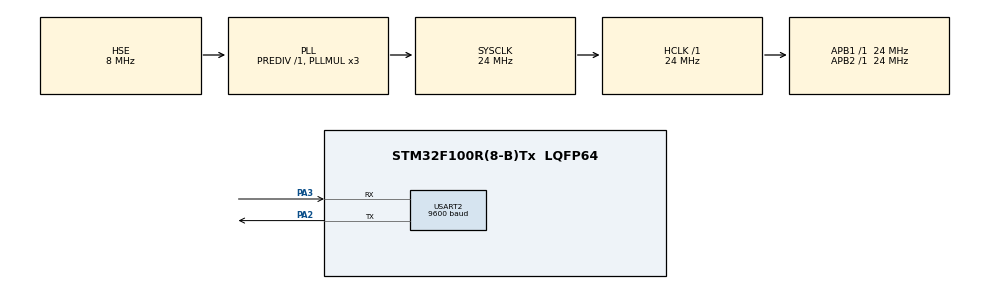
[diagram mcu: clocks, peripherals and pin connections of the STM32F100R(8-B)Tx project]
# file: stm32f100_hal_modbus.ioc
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Mcu.Family=STM32F1
Mcu.Name=STM32F100R(8-B)Tx
Mcu.Package=LQFP64
NVIC.PriorityGroup=NVIC_PRIORITYGROUP_4
NVIC.TIM6_DAC_IRQn=true\:0\:0\:false\:false\:true\:true\:true
PA13.Mode=Serial_Wire
PA13.Signal=SYS_JTMS-SWDIO
PA14.Mode=Serial_Wire
PA14.Signal=SYS_JTCK-SWCLK
PA2.Mode=Asynchronous
PA2.Signal=USART2_TX
PA3.Mode=Asynchronous
PA3.Signal=USART2_RX
PC14-OSC32_IN.Mode=LSE-External-Oscillator
PC14-OSC32_IN.Signal=RCC_OSC32_IN
PC15-OSC32_OUT.Mode=LSE-External-Oscillator
PC15-OSC32_OUT.Signal=RCC_OSC32_OUT
PD0-OSC_IN.Mode=HSE-External-Oscillator
PD0-OSC_IN.Signal=RCC_OSC_IN
PD1-OSC_OUT.Mode=HSE-External-Oscillator
PD1-OSC_OUT.Signal=RCC_OSC_OUT
ProjectManager.HeapSize=0x200
ProjectManager.StackSize=0x400
ProjectManager.TargetToolchain=STM32CubeIDE
RCC.AHBFreq_Value=24000000
RCC.APB1Freq_Value=24000000
RCC.APB1TimFreq_Value=24000000
RCC.APB2Freq_Value=24000000
RCC.APB2TimFreq_Value=24000000
RCC.HCLKFreq_Value=24000000
RCC.PLLMUL=RCC_PLL_MUL3
RCC.PLLSource=RCC_PLLSOURCE_HSE
RCC.SYSCLKFreq_VALUE=24000000
RCC.SYSCLKSource=RCC_SYSCLKSOURCE_PLLCLK
TIM6.Period=49
TIM6.Prescaler=23
USART2.BaudRate=9600
USART2.VirtualMode=VM_ASYNC
VP_TIM6_VS_ClockSourceINT.Mode=Enable_Timer
board=custom

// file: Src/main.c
/* USER CODE BEGIN Header */
/**
  ******************************************************************************
  * @file           : main.c
  * @brief          : Main program body
  ******************************************************************************
  * @attention
  *
  * <h2><center>&copy; Copyright (c) 2019 STMicroelectronics.
  * All rights reserved.</center></h2>
  *
  * This software component is licensed by ST under BSD 3-Clause license,
  * the "License"; You may not use this file except in compliance with the
  * License. You may obtain a copy of the License at:
  *                        opensource.org/licenses/BSD-3-Clause
  *
  ******************************************************************************
  */
/* USER CODE END Header */

#include "main.h"

/* USER CODE BEGIN Includes */
#include "mb.h"
#include "mbport.h"

/* USER CODE END Includes */

/* USER CODE BEGIN PD */

#define REG_INPUT_START 1000
#define REG_INPUT_NREGS 4

#define REG_HOLDING_START 1000
#define REG_HOLDING_NREGS 4

/* USER CODE END PD */

TIM_HandleTypeDef htim6;

UART_HandleTypeDef huart2;

/* USER CODE BEGIN PV */

static USHORT   usRegInputStart = REG_INPUT_START;
static USHORT   usRegInputBuf[REG_INPUT_NREGS];

static USHORT   usRegHoldingStart = REG_HOLDING_START;
static USHORT   usRegHoldingBuf[REG_HOLDING_NREGS];

/* USER CODE END PV */

void SystemClock_Config(void);
static void MX_GPIO_Init(void);
static void MX_TIM6_Init(void);
static void MX_USART2_UART_Init(void);

/* USER CODE BEGIN 0 */

eMBErrorCode
eMBRegInputCB( UCHAR * pucRegBuffer, USHORT usAddress, USHORT usNRegs )
{
    eMBErrorCode    eStatus = MB_ENOERR;
    int             iRegIndex;

    if( ( usAddress >= REG_INPUT_START )
        && ( usAddress + usNRegs <= REG_INPUT_START + REG_INPUT_NREGS ) )
    {
        iRegIndex = ( int )( usAddress - usRegInputStart );
        while( usNRegs > 0 )
        {
            *pucRegBuffer++ =
                ( unsigned char )( usRegInputBuf[iRegIndex] >> 8 );
            *pucRegBuffer++ =
                ( unsigned char )( usRegInputBuf[iRegIndex] & 0xFF );
            iRegIndex++;
            usNRegs--;
        }
    }
    else
    {
        eStatus = MB_ENOREG;
    }

    return eStatus;
}

eMBErrorCode
eMBRegHoldingCB( UCHAR * pucRegBuffer, USHORT usAddress, USHORT usNRegs, eMBRegisterMode eMode )
{
    eMBErrorCode    eStatus = MB_ENOERR;
    int             iRegIndex;

    if( ( usAddress >= REG_HOLDING_START ) &&
        ( usAddress + usNRegs <= REG_HOLDING_START + REG_HOLDING_NREGS ) )
    {
        iRegIndex = ( int )( usAddress - usRegHoldingStart );
        switch ( eMode )
        {
            /* Pass current register values to the protocol stack. */
        case MB_REG_READ:
            while( usNRegs > 0 )
            {
                *pucRegBuffer++ = ( UCHAR ) ( usRegHoldingBuf[iRegIndex] >> 8 );
                *pucRegBuffer++ = ( UCHAR ) ( usRegHoldingBuf[iRegIndex] & 0xFF );
                iRegIndex++;
                usNRegs--;
            }
            break;

            /* Update current register values with new values from the
             * protocol stack. */
        case MB_REG_WRITE:
            while( usNRegs > 0 )
            {
                usRegHoldingBuf[iRegIndex] = *pucRegBuffer++ << 8;
                usRegHoldingBuf[iRegIndex] |= *pucRegBuffer++;
                iRegIndex++;
                usNRegs--;
            }
        }
    }
    else
    {
        eStatus = MB_ENOREG;
    }
    return eStatus;
}

eMBErrorCode
eMBRegCoilsCB( UCHAR * pucRegBuffer, USHORT usAddress, USHORT usNCoils,
               eMBRegisterMode eMode )
{
    return MB_ENOREG;
}

eMBErrorCode
eMBRegDiscreteCB( UCHAR * pucRegBuffer, USHORT usAddress, USHORT usNDiscrete )
{
    return MB_ENOREG;
}

static uint32_t lock_nesting_count = 0;
void __critical_enter(void)
{
    __disable_irq();
    ++lock_nesting_count;
}
void __critical_exit(void)
{
    /* Unlock interrupts only when we are exiting the outermost nested call. */
    --lock_nesting_count;
    if (lock_nesting_count == 0) {
        __enable_irq();
    }
}

/* USER CODE END 0 */

int main(void)
{

  /* MCU Configuration--------------------------------------------------------*/

  /* Reset of all peripherals, Initializes the Flash interface and the Systick. */
  HAL_Init();

  /* Configure the system clock */
  SystemClock_Config();

  /* Initialize all configured peripherals */
  MX_GPIO_Init();
  MX_TIM6_Init();
  MX_USART2_UART_Init();
  /* USER CODE BEGIN 2 */

  	  eMBErrorCode    eStatus;
      eStatus = eMBInit( MB_RTU, 0x0A, 1, 9600, MB_PAR_NONE );

      /* Enable the Modbus Protocol Stack. */
      eStatus = eMBEnable(  );

  /* USER CODE END 2 */

  /* Infinite loop */
  while (1)
  {

    /* USER CODE BEGIN 3 */
	  ( void )eMBPoll(  );

	 /* Here we simply count the number of poll cycles. */
	    usRegInputBuf[1]++;
  }
  /* USER CODE END 3 */
}

void SystemClock_Config(void)
{
  RCC_OscInitTypeDef RCC_OscInitStruct = {0};
  RCC_ClkInitTypeDef RCC_ClkInitStruct = {0};

  /** Initializes the CPU, AHB and APB busses clocks
  */
  RCC_OscInitStruct.OscillatorType = RCC_OSCILLATORTYPE_HSE;
  RCC_OscInitStruct.HSEState = RCC_HSE_ON;
  RCC_OscInitStruct.HSEPredivValue = RCC_HSE_PREDIV_DIV1;
  RCC_OscInitStruct.PLL.PLLState = RCC_PLL_ON;
  RCC_OscInitStruct.PLL.PLLSource = RCC_PLLSOURCE_HSE;
  RCC_OscInitStruct.PLL.PLLMUL = RCC_PLL_MUL3;
  if (HAL_RCC_OscConfig(&RCC_OscInitStruct) != HAL_OK)
  {
    Error_Handler();
  }
  /** Initializes the CPU, AHB and APB busses clocks
  */
  RCC_ClkInitStruct.ClockType = RCC_CLOCKTYPE_HCLK|RCC_CLOCKTYPE_SYSCLK
                              |RCC_CLOCKTYPE_PCLK1|RCC_CLOCKTYPE_PCLK2;
  RCC_ClkInitStruct.SYSCLKSource = RCC_SYSCLKSOURCE_PLLCLK;
  RCC_ClkInitStruct.AHBCLKDivider = RCC_SYSCLK_DIV1;
  RCC_ClkInitStruct.APB1CLKDivider = RCC_HCLK_DIV1;
  RCC_ClkInitStruct.APB2CLKDivider = RCC_HCLK_DIV1;

  if (HAL_RCC_ClockConfig(&RCC_ClkInitStruct, FLASH_LATENCY_0) != HAL_OK)
  {
    Error_Handler();
  }
}

static void MX_TIM6_Init(void)
{

  TIM_MasterConfigTypeDef sMasterConfig = {0};

  htim6.Instance = TIM6;
  htim6.Init.Prescaler = 23;
  htim6.Init.CounterMode = TIM_COUNTERMODE_UP;
  htim6.Init.Period = 49;
  htim6.Init.AutoReloadPreload = TIM_AUTORELOAD_PRELOAD_DISABLE;
  if (HAL_TIM_Base_Init(&htim6) != HAL_OK)
  {
    Error_Handler();
  }
  sMasterConfig.MasterOutputTrigger = TIM_TRGO_RESET;
  sMasterConfig.MasterSlaveMode = TIM_MASTERSLAVEMODE_DISABLE;
  if (HAL_TIMEx_MasterConfigSynchronization(&htim6, &sMasterConfig) != HAL_OK)
  {
    Error_Handler();
  }

}

static void MX_USART2_UART_Init(void)
{

  huart2.Instance = USART2;
  huart2.Init.BaudRate = 9600;
  huart2.Init.WordLength = UART_WORDLENGTH_8B;
  huart2.Init.StopBits = UART_STOPBITS_1;
  huart2.Init.Parity = UART_PARITY_NONE;
  huart2.Init.Mode = UART_MODE_TX_RX;
  huart2.Init.HwFlowCtl = UART_HWCONTROL_NONE;
  huart2.Init.OverSampling = UART_OVERSAMPLING_16;
  if (HAL_UART_Init(&huart2) != HAL_OK)
  {
    Error_Handler();
  }

}

static void MX_GPIO_Init(void)
{

  /* GPIO Ports Clock Enable */
  __HAL_RCC_GPIOC_CLK_ENABLE();
  __HAL_RCC_GPIOD_CLK_ENABLE();
  __HAL_RCC_GPIOA_CLK_ENABLE();

}

void Error_Handler(void)
{
}

/************************ (C) COPYRIGHT STMicroelectronics *****END OF FILE****/
